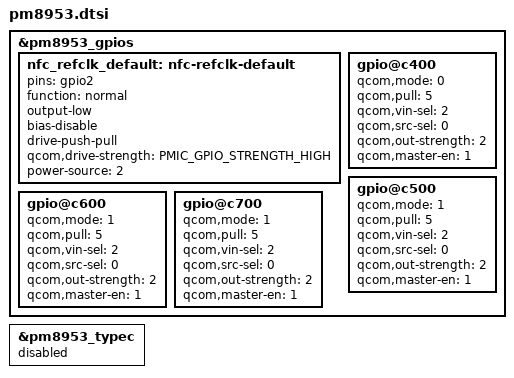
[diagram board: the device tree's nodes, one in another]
#include <dt-bindings/pinctrl/qcom,pmic-gpio.h>

&pm8953_gpios {
	nfc_refclk_default: nfc-refclk-default {
		pins = "gpio2";
		function = "normal";
		output-low;
		bias-disable;
		drive-push-pull;
		qcom,drive-strength = <PMIC_GPIO_STRENGTH_HIGH>;
		power-source = <2>;
	};

	gpio@c400 {
		qcom,mode = <0>;		/* Digital Input */
		qcom,pull = <5>;		/* No pull  */
		qcom,vin-sel = <2>;		/* VIN0 */
		qcom,src-sel = <0>;		/* GPIO */
		qcom,out-strength = <2>;        /* Medium */
		qcom,master-en = <1>;		/* Enable GPIO */
		status = "okay";
	};

	gpio@c500 { /* GPIO 6 - USB_SELECT */
		qcom,mode = <1>;		/* Digital Output */
		qcom,pull = <5>;		/* No pull  */
		qcom,vin-sel = <2>;		/* VIN0 */
		qcom,src-sel = <0>;		/* GPIO */
		qcom,out-strength = <2>;        /* Medium */
		qcom,master-en = <1>;		/* Enable GPIO */
		status = "okay";
	};

	gpio@c600 { /* GPIO 7 - USB_SS_MOD_EN */
		qcom,mode = <1>;		/* Digital Output */
		qcom,pull = <5>;		/* No pull  */
		qcom,vin-sel = <2>;		/* VIN0 */
		qcom,src-sel = <0>;		/* GPIO */
		qcom,out-strength = <2>;        /* Medium */
		qcom,master-en = <1>;		/* Enable GPIO */
		status = "okay";
	};

	gpio@c700 { /* GPIO 8 - USB_SS_MOD_MPHY_AP_EN */
		qcom,mode = <1>;		/* Digital Output */
		qcom,pull = <5>;		/* No pull  */
		qcom,vin-sel = <2>;		/* VIN0 */
		qcom,src-sel = <0>;		/* GPIO */
		qcom,out-strength = <2>;        /* Medium */
		qcom,master-en = <1>;		/* Enable GPIO */
		status = "okay";
	};
};

&pm8953_typec {
	status = "disabled";
};
